# APM32F091 register map
File version: 1.0
Registers are 32-bit, read-write, reset 0x0 unless marked. A register's access mark holds for its fields unless they carry their own. Offsets are from the block's base; [hi:lo] are bit positions.

## I2C1 — Inter-integrated circuit
Base 0x40005400
Same registers: I2C2 0x40005800
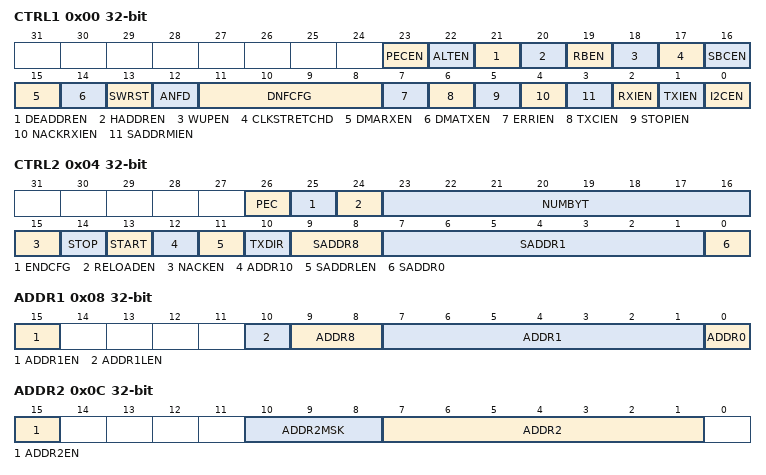
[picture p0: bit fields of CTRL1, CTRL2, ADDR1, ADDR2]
0x00 CTRL1 access per field — Control register 1
  [23] PECEN rw — PEC enable
  [22] ALTEN rw — SMBUS alert enable
  [21] DEADDREN rw — SMBus Device Default address enable
  [20] HADDREN rw — SMBus Host address enable
  [19] RBEN rw — Broadcast call enable
  [18] WUPEN rw — Wake Up enable
  [17] CLKSTRETCHD rw — Clock stretching disable
  [16] SBCEN rw — Slave byte control
  [15] DMARXEN rw — DMA reception requests enable
  [14] DMATXEN rw — DMA transmission requests enable
  [13] SWRST wo — Software reset
  [12] ANFD rw — Analog noise filter mode
  [11:8] DNFCFG rw — Digital noise filter
  [7] ERRIEN rw — Error interrupts enable
  [6] TXCIEN rw — Transfer Complete interrupt enable
  [5] STOPIEN rw — STOP detection Interrupt enable
  [4] NACKRXIEN rw — Not acknowledge received interrupt enable
  [3] SADDRMIEN rw — Address match interrupt enable (slave only)
  [2] RXIEN rw — RX Interrupt enable
  [1] TXIEN rw — TX Interrupt enable
  [0] I2CEN rw — I2C enable
0x04 CTRL2
  [26] PEC — Packet error checking byte
  [25] ENDCFG — Automatic end mode (master mode)
  [24] RELOADEN — NBYTES reload mode
  [23:16] NUMBYT — Number of bytes
  [15] NACKEN — NACK generation (slave mode)
  [14] STOP — Stop generation (master mode)
  [13] START — Start generation
  [12] ADDR10 — 10-bit address header only read direction (master receiver mode)
  [11] SADDRLEN — 10-bit addressing mode (master mode)
  [10] TXDIR — Transfer direction (master mode)
  [9:8] SADDR8 — Slave address bit 9:8 (master mode)
  [7:1] SADDR1 — Slave address bit 7:1 (master mode)
  [0] SADDR0 — Slave address bit 0 (master mode)
0x08 ADDR1 — Own address register 1
  [15] ADDR1EN — Own Address 1 enable
  [10] ADDR1LEN — Own Address 1 10-bit mode
  [9:8] ADDR8 — Interface address
  [7:1] ADDR1 — Interface address
  [0] ADDR0 — Interface address
0x0C ADDR2 — Own address register 2
  [15] ADDR2EN — Own Address 2 enable
  [10:8] ADDR2MSK — Own Address 2 masks
  [7:1] ADDR2 — Interface address
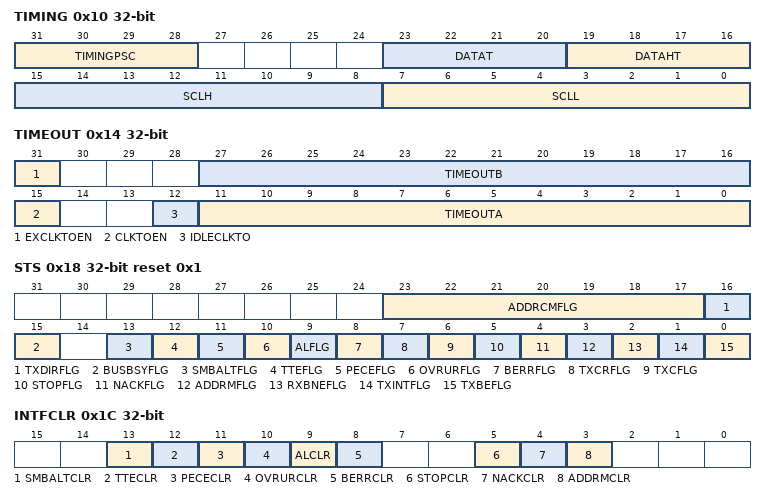
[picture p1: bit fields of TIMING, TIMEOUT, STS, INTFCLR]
0x10 TIMING
  [31:28] TIMINGPSC — Clock prescaler
  [23:20] DATAT — Data setup time
  [19:16] DATAHT — Data hold time
  [15:8] SCLH — SCL high period (master mode)
  [7:0] SCLL — SCL low period (master mode)
0x14 TIMEOUT — Status register 1
  [31] EXCLKTOEN — Extended clock timeout enable
  [27:16] TIMEOUTB — Bus timeout B
  [15] CLKTOEN — Clock timeout enable
  [12] IDLECLKTO — Idle clock timeout detection
  [11:0] TIMEOUTA — Bus timeout A
0x18 STS access per field reset 0x1 — Interrupt and Status register
  [23:17] ADDRCMFLG ro — Address match code (Slave mode)
  [16] TXDIRFLG ro — Transfer direction (Slave mode)
  [15] BUSBSYFLG ro — Bus busy
  [13] SMBALTFLG ro — SMBus alert
  [12] TTEFLG ro — Timeout or t_low detection flag
  [11] PECEFLG ro — PEC Error in reception
  [10] OVRURFLG ro — Overrun/Underrun (slave mode)
  [9] ALFLG ro — Arbitration lost
  [8] BERRFLG ro — Bus error
  [7] TXCRFLG ro — Transfer Complete Reload
  [6] TXCFLG ro — Transfer Complete (master mode)
  [5] STOPFLG ro — Stop detection flag
  [4] NACKFLG ro — Not acknowledge received flag
  [3] ADDRMFLG ro — Address matched (slave mode)
  [2] RXBNEFLG ro — Receive data register not empty (receivers)
  [1] TXINTFLG rw — Transmit interrupt status (transmitters)
  [0] TXBEFLG rw — Transmit data register empty (transmitters)
0x1C INTFCLR wo — Interrupt clear register
  [13] SMBALTCLR — Alert flag clear
  [12] TTECLR — Timeout detection flag clear
  [11] PECECLR — PEC Error flag clear
  [10] OVRURCLR — Overrun/Underrun flag clear
  [9] ALCLR — Arbitration lost flag clear
  [8] BERRCLR — Bus error flag clear
  [5] STOPCLR — Stop detection flag clear
  [4] NACKCLR — Not Acknowledge flag clear
  [3] ADDRMCLR — Address Matched flag clear
0x20 PEC ro — PEC data register
  [7:0] PEC — Packet error checking data
0x24 RXDATA ro — Receive data register
  [7:0] RXDATA — 8-bit receive data
0x28 TXDATA — Transmit data register
  [7:0] TXDATA — 8-bit transmit data
